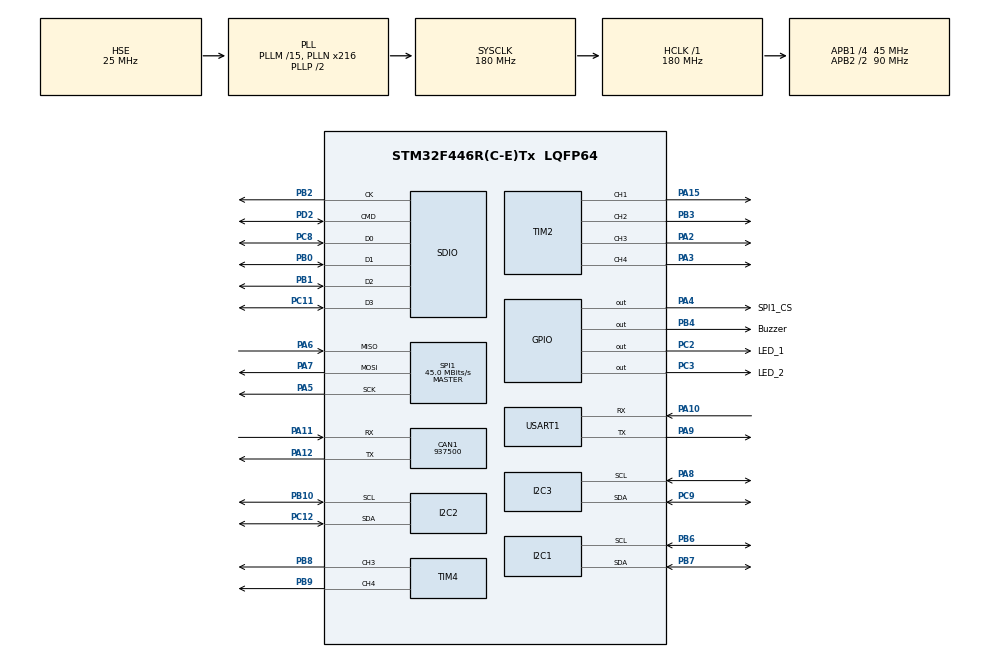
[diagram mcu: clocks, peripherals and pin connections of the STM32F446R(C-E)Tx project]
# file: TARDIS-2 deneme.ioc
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CAN1.BS1=CAN_BS1_1TQ
CAN1.BS2=CAN_BS2_1TQ
CAN1.CalculateBaudRate=937500
CAN1.CalculateTimeBit=1066
CAN1.CalculateTimeQuantum=355.55555555555554
FREERTOS.Tasks01=defaultTask,0,128,StartDefaultTask,Default,NULL,Dynamic,NULL,NULL
FREERTOS.configUSE_NEWLIB_REENTRANT=1
Mcu.Family=STM32F4
Mcu.Name=STM32F446R(C-E)Tx
Mcu.Package=LQFP64
NVIC.PriorityGroup=NVIC_PRIORITYGROUP_4
NVIC.TIM1_UP_TIM10_IRQn=true\:15\:0\:false\:false\:true\:false\:false\:true\:true
NVIC.TimeBase=TIM1_UP_TIM10_IRQn
NVIC.TimeBaseIP=TIM1
PA10.Mode=Asynchronous
PA10.Signal=USART1_RX
PA11.Mode=CAN_Activate
PA11.Signal=CAN1_RX
PA12.Mode=CAN_Activate
PA12.Signal=CAN1_TX
PA15.Signal=S_TIM2_CH1_ETR
PA2.Signal=S_TIM2_CH3
PA3.Signal=S_TIM2_CH4
PA4.GPIO_Label=SPI1_CS
PA4.Signal=GPIO_Output
PA5.Mode=Full_Duplex_Master
PA5.Signal=SPI1_SCK
PA6.Mode=Full_Duplex_Master
PA6.Signal=SPI1_MISO
PA7.Mode=Full_Duplex_Master
PA7.Signal=SPI1_MOSI
PA8.Mode=I2C
PA8.Signal=I2C3_SCL
PA9.Mode=Asynchronous
PA9.Signal=USART1_TX
PB0.Mode=SD_4_bits_Wide_bus
PB0.Signal=SDIO_D1
PB1.Mode=SD_4_bits_Wide_bus
PB1.Signal=SDIO_D2
PB10.Mode=I2C
PB10.Signal=I2C2_SCL
PB2.Mode=SD_4_bits_Wide_bus
PB2.Signal=SDIO_CK
PB3.Signal=S_TIM2_CH2
PB4.GPIO_Label=Buzzer
PB4.Signal=GPIO_Output
PB6.Mode=I2C
PB6.Signal=I2C1_SCL
PB7.Mode=I2C
PB7.Signal=I2C1_SDA
PB8.Signal=S_TIM4_CH3
PB9.Signal=S_TIM4_CH4
PC11.Mode=SD_4_bits_Wide_bus
PC11.Signal=SDIO_D3
PC12.Mode=I2C
PC12.Signal=I2C2_SDA
PC2.GPIO_Label=LED_1
PC2.Signal=GPIO_Output
PC3.GPIO_Label=LED_2
PC3.Signal=GPIO_Output
PC8.Mode=SD_4_bits_Wide_bus
PC8.Signal=SDIO_D0
PC9.Mode=I2C
PC9.Signal=I2C3_SDA
PD2.Mode=SD_4_bits_Wide_bus
PD2.Signal=SDIO_CMD
PH0-OSC_IN.Mode=HSE-External-Oscillator
PH0-OSC_IN.Signal=RCC_OSC_IN
PH1-OSC_OUT.Mode=HSE-External-Oscillator
PH1-OSC_OUT.Signal=RCC_OSC_OUT
ProjectManager.HeapSize=0x200
ProjectManager.StackSize=0x400
ProjectManager.TargetToolchain=STM32CubeIDE
RCC.AHBFreq_Value=180000000
RCC.APB1CLKDivider=RCC_HCLK_DIV4
RCC.APB1Freq_Value=45000000
RCC.APB1TimFreq_Value=90000000
RCC.APB2CLKDivider=RCC_HCLK_DIV2
RCC.APB2Freq_Value=90000000
RCC.APB2TimFreq_Value=180000000
RCC.CortexFreq_Value=180000000
RCC.HCLKFreq_Value=180000000
RCC.HSE_VALUE=25000000
RCC.PLLM=15
RCC.PLLN=216
RCC.PLLQ=8
RCC.PLLSourceVirtual=RCC_PLLSOURCE_HSE
RCC.SYSCLKFreq_VALUE=180000000
RCC.SYSCLKSource=RCC_SYSCLKSOURCE_PLLCLK
RCC.USBFreq_Value=45000000
RCC.VCOOutputFreq_Value=360000000
SH.S_TIM2_CH1_ETR.0=TIM2_CH1,PWM Generation1 CH1
SH.S_TIM2_CH2.0=TIM2_CH2,PWM Generation2 CH2
SH.S_TIM2_CH3.0=TIM2_CH3,PWM Generation3 CH3
SH.S_TIM2_CH4.0=TIM2_CH4,PWM Generation4 CH4
SH.S_TIM4_CH3.0=TIM4_CH3,PWM Generation3 CH3
SH.S_TIM4_CH4.0=TIM4_CH4,PWM Generation4 CH4
SPI1.BaudRatePrescaler=SPI_BAUDRATEPRESCALER_2
SPI1.CalculateBaudRate=45.0 MBits/s
SPI1.Direction=SPI_DIRECTION_2LINES
SPI1.Mode=SPI_MODE_MASTER
SPI1.VirtualType=VM_MASTER
TIM2.Channel-PWM\ Generation1\ CH1=TIM_CHANNEL_1
TIM2.Channel-PWM\ Generation2\ CH2=TIM_CHANNEL_2
TIM2.Channel-PWM\ Generation3\ CH3=TIM_CHANNEL_3
TIM2.Channel-PWM\ Generation4\ CH4=TIM_CHANNEL_4
TIM4.Channel-PWM\ Generation3\ CH3=TIM_CHANNEL_3
TIM4.Channel-PWM\ Generation4\ CH4=TIM_CHANNEL_4
USART1.VirtualMode=VM_ASYNC
VP_FREERTOS_VS_CMSIS_V1.Mode=CMSIS_V1
VP_SYS_VS_tim1.Mode=TIM1
VP_TIM6_VS_ClockSourceINT.Mode=Enable_Timer
board=custom

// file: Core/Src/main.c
/* USER CODE BEGIN Header */
/**
  ******************************************************************************
  * @file           : main.c
  * @brief          : Main program body
  ******************************************************************************
  * @attention
  *
  * Copyright (c) 2024 STMicroelectronics.
  * All rights reserved.
  *
  * This software is licensed under terms that can be found in the LICENSE file
  * in the root directory of this software component.
  * If no LICENSE file comes with this software, it is provided AS-IS.
  *
  ******************************************************************************
  */
/* USER CODE END Header */
#include "main.h"
#include "cmsis_os.h"
#include "can.h"
#include "i2c.h"
#include "sdio.h"
#include "spi.h"
#include "tim.h"
#include "usart.h"
#include "gpio.h"

void SystemClock_Config(void);
void MX_FREERTOS_Init(void);

int main(void)
{

  /* MCU Configuration--------------------------------------------------------*/

  /* Reset of all peripherals, Initializes the Flash interface and the Systick. */
  HAL_Init();

  /* Configure the system clock */
  SystemClock_Config();

  /* Initialize all configured peripherals */
  MX_GPIO_Init();
  MX_CAN1_Init();
  MX_I2C2_Init();
  MX_I2C3_Init();
  MX_SDIO_SD_Init();
  MX_SPI1_Init();
  MX_TIM2_Init();
  MX_TIM4_Init();
  MX_USART1_UART_Init();
  MX_TIM6_Init();
  MX_I2C1_Init();

  /* Call init function for freertos objects (in freertos.c) */
  MX_FREERTOS_Init();

  /* Start scheduler */
  osKernelStart();
  /* We should never get here as control is now taken by the scheduler */
  /* Infinite loop */
  while (1)
  {

  }
}

void SystemClock_Config(void)
{
  RCC_OscInitTypeDef RCC_OscInitStruct = {0};
  RCC_ClkInitTypeDef RCC_ClkInitStruct = {0};

  /** Configure the main internal regulator output voltage
  */
  __HAL_RCC_PWR_CLK_ENABLE();
  __HAL_PWR_VOLTAGESCALING_CONFIG(PWR_REGULATOR_VOLTAGE_SCALE1);

  /** Initializes the RCC Oscillators according to the specified parameters
  * in the RCC_OscInitTypeDef structure.
  */
  RCC_OscInitStruct.OscillatorType = RCC_OSCILLATORTYPE_HSE;
  RCC_OscInitStruct.HSEState = RCC_HSE_ON;
  RCC_OscInitStruct.PLL.PLLState = RCC_PLL_ON;
  RCC_OscInitStruct.PLL.PLLSource = RCC_PLLSOURCE_HSE;
  RCC_OscInitStruct.PLL.PLLM = 15;
  RCC_OscInitStruct.PLL.PLLN = 216;
  RCC_OscInitStruct.PLL.PLLP = RCC_PLLP_DIV2;
  RCC_OscInitStruct.PLL.PLLQ = 8;
  RCC_OscInitStruct.PLL.PLLR = 2;
  if (HAL_RCC_OscConfig(&RCC_OscInitStruct) != HAL_OK)
  {
    Error_Handler();
  }

  /** Activate the Over-Drive mode
  */
  if (HAL_PWREx_EnableOverDrive() != HAL_OK)
  {
    Error_Handler();
  }

  /** Initializes the CPU, AHB and APB buses clocks
  */
  RCC_ClkInitStruct.ClockType = RCC_CLOCKTYPE_HCLK|RCC_CLOCKTYPE_SYSCLK
                              |RCC_CLOCKTYPE_PCLK1|RCC_CLOCKTYPE_PCLK2;
  RCC_ClkInitStruct.SYSCLKSource = RCC_SYSCLKSOURCE_PLLCLK;
  RCC_ClkInitStruct.AHBCLKDivider = RCC_SYSCLK_DIV1;
  RCC_ClkInitStruct.APB1CLKDivider = RCC_HCLK_DIV4;
  RCC_ClkInitStruct.APB2CLKDivider = RCC_HCLK_DIV2;

  if (HAL_RCC_ClockConfig(&RCC_ClkInitStruct, FLASH_LATENCY_5) != HAL_OK)
  {
    Error_Handler();
  }
}

void HAL_TIM_PeriodElapsedCallback(TIM_HandleTypeDef *htim)
{
  if (htim->Instance == TIM1) {
    HAL_IncTick();
  }
}

void Error_Handler(void)
{
  __disable_irq();
  while (1)
  {
  }
}

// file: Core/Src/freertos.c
/* USER CODE BEGIN Header */
/**
  ******************************************************************************
  * File Name          : freertos.c
  * Description        : Code for freertos applications
  ******************************************************************************
  * @attention
  *
  * Copyright (c) 2024 STMicroelectronics.
  * All rights reserved.
  *
  * This software is licensed under terms that can be found in the LICENSE file
  * in the root directory of this software component.
  * If no LICENSE file comes with this software, it is provided AS-IS.
  *
  ******************************************************************************
  */
/* USER CODE END Header */

#include "FreeRTOS.h"
#include "task.h"
#include "main.h"
#include "cmsis_os.h"

osThreadId defaultTaskHandle;

void StartDefaultTask(void const * argument);

void MX_FREERTOS_Init(void); /* (MISRA C 2004 rule 8.1) */

/* GetIdleTaskMemory prototype (linked to static allocation support) */
void vApplicationGetIdleTaskMemory( StaticTask_t **ppxIdleTaskTCBBuffer, StackType_t **ppxIdleTaskStackBuffer, uint32_t *pulIdleTaskStackSize );

/* USER CODE BEGIN GET_IDLE_TASK_MEMORY */
static StaticTask_t xIdleTaskTCBBuffer;
static StackType_t xIdleStack[configMINIMAL_STACK_SIZE];

void vApplicationGetIdleTaskMemory( StaticTask_t **ppxIdleTaskTCBBuffer, StackType_t **ppxIdleTaskStackBuffer, uint32_t *pulIdleTaskStackSize )
{
  *ppxIdleTaskTCBBuffer = &xIdleTaskTCBBuffer;
  *ppxIdleTaskStackBuffer = &xIdleStack[0];
  *pulIdleTaskStackSize = configMINIMAL_STACK_SIZE;
  /* place for user code */
}
/* USER CODE END GET_IDLE_TASK_MEMORY */

void MX_FREERTOS_Init(void) {

  /* Create the thread(s) */
  /* definition and creation of defaultTask */
  osThreadDef(defaultTask, StartDefaultTask, osPriorityNormal, 0, 128);
  defaultTaskHandle = osThreadCreate(osThread(defaultTask), NULL);

}

void StartDefaultTask(void const * argument)
{
  /* USER CODE BEGIN StartDefaultTask */
  /* Infinite loop */
  for(;;)
  {
	  //HAL_GPIO_WritePin(GPIOB, GPIO_PIN_4, GPIO_PIN_SET);
	  	  HAL_GPIO_WritePin(GPIOB, GPIO_PIN_4, GPIO_PIN_SET);
	  	  HAL_GPIO_WritePin(GPIOB, GPIO_PIN_4, GPIO_PIN_RESET);
	  	  osDelay(500);
	  	  HAL_GPIO_WritePin(GPIOB, GPIO_PIN_4, GPIO_PIN_SET);
	  	  HAL_GPIO_WritePin(GPIOB, GPIO_PIN_4, GPIO_PIN_RESET);
	  	  osDelay(500);
    osDelay(1);
  }
  /* USER CODE END StartDefaultTask */
}
